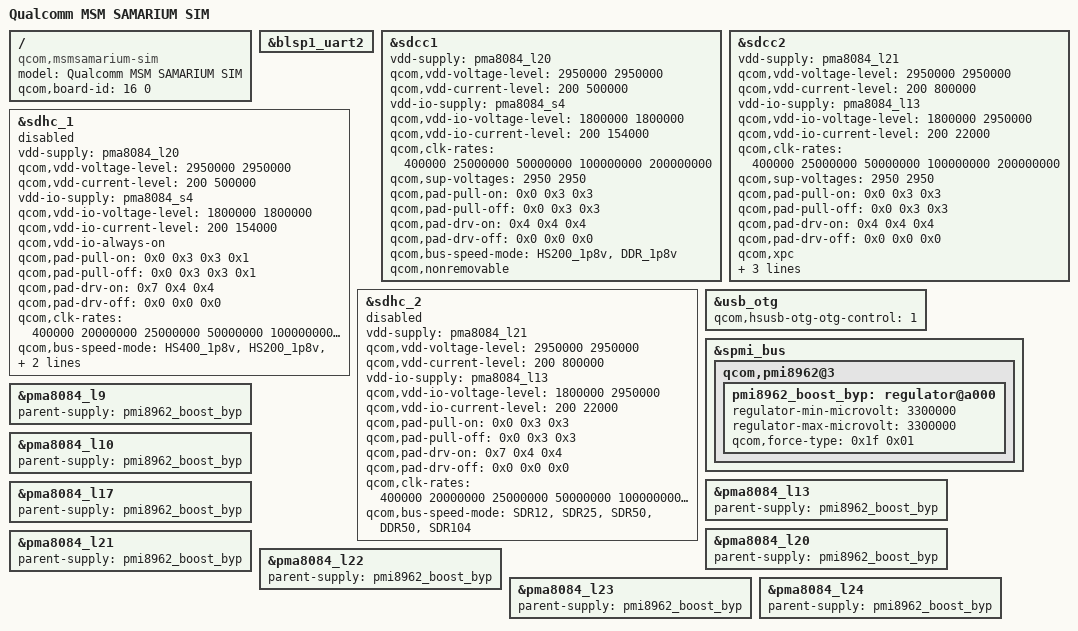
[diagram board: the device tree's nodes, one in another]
/* Copyright (c) 2013, The Linux Foundation. All rights reserved.
 *
 * This program is free software; you can redistribute it and/or modify
 * it under the terms of the GNU General Public License version 2 and
 * only version 2 as published by the Free Software Foundation.
 *
 * This program is distributed in the hope that it will be useful,
 * but WITHOUT ANY WARRANTY; without even the implied warranty of
 * MERCHANTABILITY or FITNESS FOR A PARTICULAR PURPOSE.  See the
 * GNU General Public License for more details.
 */

/dts-v1/;

#include "msmsamarium.dtsi"
#include "msm-pmi8962.dtsi"

/ {
	model = "Qualcomm MSM SAMARIUM SIM";
	compatible = "qcom,msmsamarium-sim", "qcom,msmsamarium", "qcom,sim";
	qcom,board-id = <16 0>;
};

&blsp1_uart2{
	status = "ok";
};

&sdcc1 {
	vdd-supply = <&pma8084_l20>;
	qcom,vdd-voltage-level = <2950000 2950000>;
	qcom,vdd-current-level = <200 500000>;

	vdd-io-supply = <&pma8084_s4>;
	qcom,vdd-io-voltage-level = <1800000 1800000>;
	qcom,vdd-io-current-level = <200 154000>;

	qcom,clk-rates = <400000 25000000 50000000 100000000 200000000>;
	qcom,sup-voltages = <2950 2950>;

	qcom,pad-pull-on = <0x0 0x3 0x3>; /* no-pull, pull-up, pull-up */
	qcom,pad-pull-off = <0x0 0x3 0x3>; /* no-pull, pull-up, pull-up */
	qcom,pad-drv-on = <0x4 0x4 0x4>; /* 10mA, 10mA, 10mA */
	qcom,pad-drv-off = <0x0 0x0 0x0>; /* 2mA, 2mA, 2mA */

	qcom,bus-speed-mode = "HS200_1p8v", "DDR_1p8v";
	qcom,nonremovable;
	status = "ok";
};

&sdcc2 {
	vdd-supply = <&pma8084_l21>;
	qcom,vdd-voltage-level = <2950000 2950000>;
	qcom,vdd-current-level = <200 800000>;

	vdd-io-supply = <&pma8084_l13>;
	qcom,vdd-io-voltage-level = <1800000 2950000>;
	qcom,vdd-io-current-level = <200 22000>;

	qcom,clk-rates = <400000 25000000 50000000 100000000 200000000>;
	qcom,sup-voltages = <2950 2950>;

	qcom,pad-pull-on = <0x0 0x3 0x3>; /* no-pull, pull-up, pull-up */
	qcom,pad-pull-off = <0x0 0x3 0x3>; /* no-pull, pull-up, pull-up */
	qcom,pad-drv-on = <0x4 0x4 0x4>; /* 10mA, 10mA, 10mA */
	qcom,pad-drv-off = <0x0 0x0 0x0>; /* 2mA, 2mA, 2mA */

	qcom,xpc;
	qcom,bus-speed-mode = "SDR12", "SDR25", "SDR50", "DDR50", "SDR104";
	qcom,current-limit = <800>;

	status = "ok";
};

&sdhc_1 {
	vdd-supply = <&pma8084_l20>;
	qcom,vdd-voltage-level = <2950000 2950000>;
	qcom,vdd-current-level = <200 500000>;

	vdd-io-supply = <&pma8084_s4>;
	qcom,vdd-io-voltage-level = <1800000 1800000>;
	qcom,vdd-io-current-level = <200 154000>;
	qcom,vdd-io-always-on;

	qcom,pad-pull-on = <0x0 0x3 0x3 0x1>; /* no-pull, pull-up, pull-up, pull-down */
	qcom,pad-pull-off = <0x0 0x3 0x3 0x1>; /* no-pull, pull-up, pull-up, pull-down */
	qcom,pad-drv-on = <0x7 0x4 0x4>; /* 16mA, 10mA, 10mA */
	qcom,pad-drv-off = <0x0 0x0 0x0>; /* 2mA, 2mA, 2mA */

	qcom,clk-rates = <400000 20000000 25000000 50000000 100000000 200000000 400000000>;
	qcom,bus-speed-mode = "HS400_1p8v", "HS200_1p8v", "DDR_1p8v";
	qcom,nonremovable;

	status = "disabled";
};

&sdhc_2 {
	vdd-supply = <&pma8084_l21>;
	qcom,vdd-voltage-level = <2950000 2950000>;
	qcom,vdd-current-level = <200 800000>;

	vdd-io-supply = <&pma8084_l13>;
	qcom,vdd-io-voltage-level = <1800000 2950000>;
	qcom,vdd-io-current-level = <200 22000>;

	qcom,pad-pull-on = <0x0 0x3 0x3>; /* no-pull, pull-up, pull-up */
	qcom,pad-pull-off = <0x0 0x3 0x3>; /* no-pull, pull-up, pull-up */
	qcom,pad-drv-on = <0x7 0x4 0x4>; /* 16mA, 10mA, 10mA */
	qcom,pad-drv-off = <0x0 0x0 0x0>; /* 2mA, 2mA, 2mA */

	qcom,clk-rates = <400000 20000000 25000000 50000000 100000000 200000000>;
	qcom,bus-speed-mode = "SDR12", "SDR25", "SDR50", "DDR50", "SDR104";

	status = "disabled";
};

&usb_otg {
	status = "ok";
	qcom,hsusb-otg-otg-control = <1>;
};

&spmi_bus {
	qcom,pmi8962@3 {
		pmi8962_boost_byp: regulator@a000 {
			regulator-min-microvolt = <3300000>;
			regulator-max-microvolt = <3300000>;
			qcom,force-type = <0x1f 0x01>;
			status = "ok";
		};
	};
};

&pma8084_l9 {
	parent-supply = <&pmi8962_boost_byp>;
};

&pma8084_l10 {
	parent-supply = <&pmi8962_boost_byp>;
};

&pma8084_l13 {
	parent-supply = <&pmi8962_boost_byp>;
};

&pma8084_l17 {
	parent-supply = <&pmi8962_boost_byp>;
};

&pma8084_l20 {
	parent-supply = <&pmi8962_boost_byp>;
};

&pma8084_l21 {
	parent-supply = <&pmi8962_boost_byp>;
};

&pma8084_l22 {
	parent-supply = <&pmi8962_boost_byp>;
};

&pma8084_l23 {
	parent-supply = <&pmi8962_boost_byp>;
};

&pma8084_l24 {
	parent-supply = <&pmi8962_boost_byp>;
};
